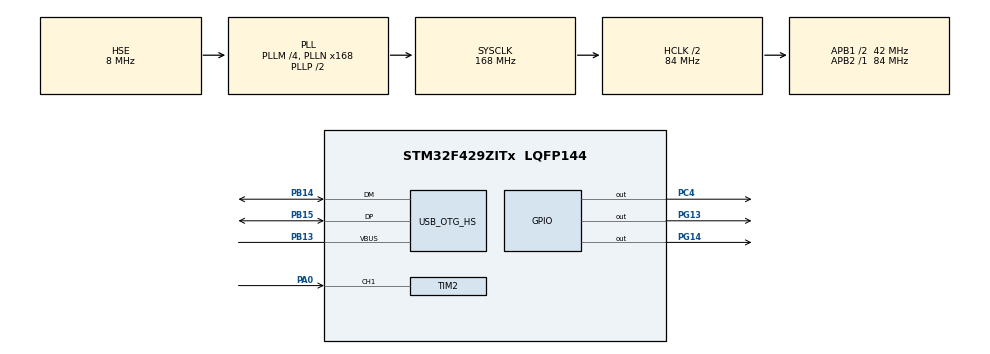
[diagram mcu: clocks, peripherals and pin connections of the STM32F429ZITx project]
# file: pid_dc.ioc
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Mcu.Family=STM32F4
Mcu.Name=STM32F429ZITx
Mcu.Package=LQFP144
NVIC.PriorityGroup=NVIC_PRIORITYGROUP_4
NVIC.TIM2_IRQn=true\:0\:0\:false\:false\:true\:true\:true
PA0/WKUP.Signal=S_TIM2_CH1_ETR
PB13.Mode=Activate_VBUS_FS
PB13.Signal=USB_OTG_HS_VBUS
PB14.Mode=Host_FS
PB14.Signal=USB_OTG_HS_DM
PB15.Mode=Host_FS
PB15.Signal=USB_OTG_HS_DP
PC4.Signal=GPIO_Output
PG13.Signal=GPIO_Output
PG14.Signal=GPIO_Output
PH0/OSC_IN.Mode=HSE-External-Oscillator
PH0/OSC_IN.Signal=RCC_OSC_IN
PH1/OSC_OUT.Mode=HSE-External-Oscillator
PH1/OSC_OUT.Signal=RCC_OSC_OUT
ProjectManager.HeapSize=0x200
ProjectManager.StackSize=0x400
ProjectManager.TargetToolchain=MDK-ARM V5
RCC.48MHZClocksFreq_Value=48000000
RCC.AHBCLKDivider=RCC_SYSCLK_DIV2
RCC.AHBFreq_Value=84000000
RCC.APB1CLKDivider=RCC_HCLK_DIV2
RCC.APB1Freq_Value=42000000
RCC.APB1TimFreq_Value=84000000
RCC.APB2Freq_Value=84000000
RCC.APB2TimFreq_Value=84000000
RCC.CortexFreq_Value=84000000
RCC.HCLKFreq_Value=84000000
RCC.HSE_VALUE=8000000
RCC.HSI_VALUE=16000000
RCC.LSE_VALUE=32768
RCC.PLLM=4
RCC.PLLN=168
RCC.PLLQ=7
RCC.SYSCLKFreq_VALUE=168000000
RCC.SYSCLKSource=RCC_SYSCLKSOURCE_PLLCLK
RCC.VCOOutputFreq_Value=336000000
SH.S_TIM2_CH1_ETR.0=TIM2_CH1,TriggerSource_TI1FP1
TIM2.Period=16
TIM2.Slave_TriggerFilter=15
USB_OTG_HS.VirtualMode-Host_FS=Host_FS
VP_TIM2_VS_ControllerModeClock.Mode=Clock Mode
board=custom

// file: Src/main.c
/* USER CODE BEGIN Header */
/**
  ******************************************************************************
  * @file           : main.c
  * @brief          : Main program body
  ******************************************************************************
  * @attention
  *
  * <h2><center>&copy; Copyright (c) 2019 STMicroelectronics.
  * All rights reserved.</center></h2>
  *
  * This software component is licensed by ST under Ultimate Liberty license
  * SLA0044, the "License"; You may not use this file except in compliance with
  * the License. You may obtain a copy of the License at:
  *                             www.st.com/SLA0044
  *
  ******************************************************************************
  */
/* USER CODE END Header */

#include "main.h"

TIM_HandleTypeDef htim2;

HCD_HandleTypeDef hhcd_USB_OTG_HS;

/* USER CODE BEGIN PV */
uint8_t count_value=0;
/* USER CODE END PV */

void SystemClock_Config(void);
static void MX_GPIO_Init(void);
static void MX_TIM2_Init(void);
static void MX_USB_OTG_HS_HCD_Init(void);
/* USER CODE BEGIN PFP */
	int flag;
/* USER CODE END PFP */

int main(void)
{

  /* MCU Configuration--------------------------------------------------------*/

  /* Reset of all peripherals, Initializes the Flash interface and the Systick. */
  HAL_Init();

  /* Configure the system clock */
  SystemClock_Config();

  /* Initialize all configured peripherals */
  MX_GPIO_Init();
  MX_TIM2_Init();
  MX_USB_OTG_HS_HCD_Init();
  /* USER CODE BEGIN 2 */
	HAL_TIM_Base_Start_IT(&htim2);

  /* USER CODE END 2 */

  /* Infinite loop */
  while (1)
  {
		count_value=__HAL_TIM_GET_COUNTER(&htim2);
		HAL_GPIO_TogglePin(GPIOG,GPIO_PIN_14);
		HAL_Delay(1000);

  }
}

void HAL_TIM_PeriodElapsedCallback(TIM_HandleTypeDef *htim)
	{
		if(htim->Instance==htim2.Instance)
		{
			flag++;
			HAL_GPIO_TogglePin(GPIOG,GPIO_PIN_13);
		}
	}

void SystemClock_Config(void)
{
  RCC_OscInitTypeDef RCC_OscInitStruct = {0};
  RCC_ClkInitTypeDef RCC_ClkInitStruct = {0};

  /** Configure the main internal regulator output voltage
  */
  __HAL_RCC_PWR_CLK_ENABLE();
  __HAL_PWR_VOLTAGESCALING_CONFIG(PWR_REGULATOR_VOLTAGE_SCALE3);
  /** Initializes the CPU, AHB and APB busses clocks
  */
  RCC_OscInitStruct.OscillatorType = RCC_OSCILLATORTYPE_HSE;
  RCC_OscInitStruct.HSEState = RCC_HSE_ON;
  RCC_OscInitStruct.PLL.PLLState = RCC_PLL_ON;
  RCC_OscInitStruct.PLL.PLLSource = RCC_PLLSOURCE_HSE;
  RCC_OscInitStruct.PLL.PLLM = 4;
  RCC_OscInitStruct.PLL.PLLN = 168;
  RCC_OscInitStruct.PLL.PLLP = RCC_PLLP_DIV2;
  RCC_OscInitStruct.PLL.PLLQ = 7;
  if (HAL_RCC_OscConfig(&RCC_OscInitStruct) != HAL_OK)
  {
    Error_Handler();
  }
  /** Initializes the CPU, AHB and APB busses clocks
  */
  RCC_ClkInitStruct.ClockType = RCC_CLOCKTYPE_HCLK|RCC_CLOCKTYPE_SYSCLK
                              |RCC_CLOCKTYPE_PCLK1|RCC_CLOCKTYPE_PCLK2;
  RCC_ClkInitStruct.SYSCLKSource = RCC_SYSCLKSOURCE_PLLCLK;
  RCC_ClkInitStruct.AHBCLKDivider = RCC_SYSCLK_DIV2;
  RCC_ClkInitStruct.APB1CLKDivider = RCC_HCLK_DIV2;
  RCC_ClkInitStruct.APB2CLKDivider = RCC_HCLK_DIV1;

  if (HAL_RCC_ClockConfig(&RCC_ClkInitStruct, FLASH_LATENCY_2) != HAL_OK)
  {
    Error_Handler();
  }
}

static void MX_TIM2_Init(void)
{

  TIM_SlaveConfigTypeDef sSlaveConfig = {0};
  TIM_MasterConfigTypeDef sMasterConfig = {0};

  htim2.Instance = TIM2;
  htim2.Init.Prescaler = 0;
  htim2.Init.CounterMode = TIM_COUNTERMODE_UP;
  htim2.Init.Period = 1;
  htim2.Init.ClockDivision = TIM_CLOCKDIVISION_DIV1;
  htim2.Init.AutoReloadPreload = TIM_AUTORELOAD_PRELOAD_DISABLE;
  if (HAL_TIM_Base_Init(&htim2) != HAL_OK)
  {
    Error_Handler();
  }
  sSlaveConfig.SlaveMode = TIM_SLAVEMODE_EXTERNAL1;
  sSlaveConfig.InputTrigger = TIM_TS_TI1FP1;
  sSlaveConfig.TriggerPolarity = TIM_TRIGGERPOLARITY_RISING;
  sSlaveConfig.TriggerFilter = 15;
  if (HAL_TIM_SlaveConfigSynchro(&htim2, &sSlaveConfig) != HAL_OK)
  {
    Error_Handler();
  }
  sMasterConfig.MasterOutputTrigger = TIM_TRGO_RESET;
  sMasterConfig.MasterSlaveMode = TIM_MASTERSLAVEMODE_DISABLE;
  if (HAL_TIMEx_MasterConfigSynchronization(&htim2, &sMasterConfig) != HAL_OK)
  {
    Error_Handler();
  }

}

static void MX_USB_OTG_HS_HCD_Init(void)
{

  hhcd_USB_OTG_HS.Instance = USB_OTG_HS;
  hhcd_USB_OTG_HS.Init.Host_channels = 12;
  hhcd_USB_OTG_HS.Init.speed = HCD_SPEED_FULL;
  hhcd_USB_OTG_HS.Init.dma_enable = DISABLE;
  hhcd_USB_OTG_HS.Init.phy_itface = USB_OTG_EMBEDDED_PHY;
  hhcd_USB_OTG_HS.Init.Sof_enable = DISABLE;
  hhcd_USB_OTG_HS.Init.low_power_enable = DISABLE;
  hhcd_USB_OTG_HS.Init.vbus_sensing_enable = DISABLE;
  hhcd_USB_OTG_HS.Init.use_external_vbus = DISABLE;
  if (HAL_HCD_Init(&hhcd_USB_OTG_HS) != HAL_OK)
  {
    Error_Handler();
  }

}

static void MX_GPIO_Init(void)
{
  GPIO_InitTypeDef GPIO_InitStruct = {0};

  /* GPIO Ports Clock Enable */
  __HAL_RCC_GPIOH_CLK_ENABLE();
  __HAL_RCC_GPIOA_CLK_ENABLE();
  __HAL_RCC_GPIOC_CLK_ENABLE();
  __HAL_RCC_GPIOB_CLK_ENABLE();
  __HAL_RCC_GPIOG_CLK_ENABLE();

  /*Configure GPIO pin Output Level */
  HAL_GPIO_WritePin(GPIOC, GPIO_PIN_4, GPIO_PIN_RESET);

  /*Configure GPIO pin Output Level */
  HAL_GPIO_WritePin(GPIOG, GPIO_PIN_13|GPIO_PIN_14, GPIO_PIN_RESET);

  /*Configure GPIO pin : PC4 */
  GPIO_InitStruct.Pin = GPIO_PIN_4;
  GPIO_InitStruct.Mode = GPIO_MODE_OUTPUT_PP;
  GPIO_InitStruct.Pull = GPIO_NOPULL;
  GPIO_InitStruct.Speed = GPIO_SPEED_FREQ_LOW;
  HAL_GPIO_Init(GPIOC, &GPIO_InitStruct);

  /*Configure GPIO pins : PG13 PG14 */
  GPIO_InitStruct.Pin = GPIO_PIN_13|GPIO_PIN_14;
  GPIO_InitStruct.Mode = GPIO_MODE_OUTPUT_PP;
  GPIO_InitStruct.Pull = GPIO_NOPULL;
  GPIO_InitStruct.Speed = GPIO_SPEED_FREQ_LOW;
  HAL_GPIO_Init(GPIOG, &GPIO_InitStruct);

}

void Error_Handler(void)
{
}

/************************ (C) COPYRIGHT STMicroelectronics *****END OF FILE****/
